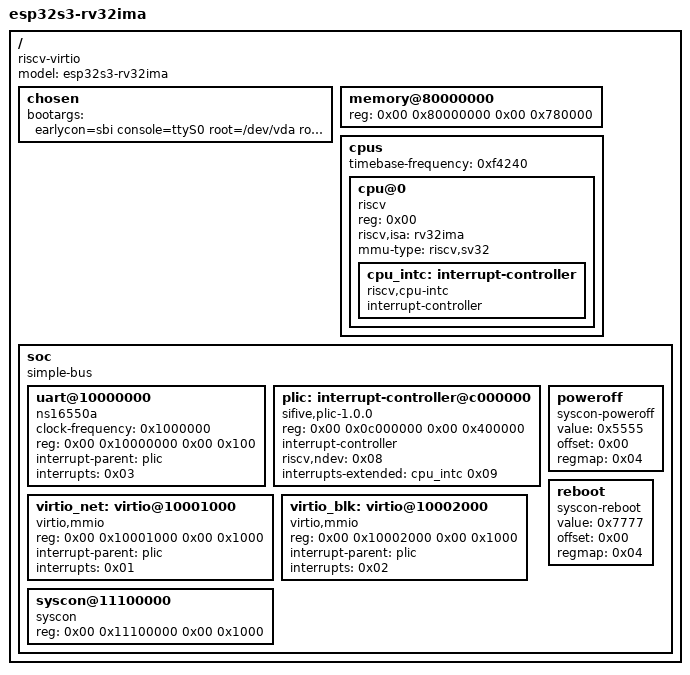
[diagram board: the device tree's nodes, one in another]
/dts-v1/;

/ {
	#address-cells = <0x02>;
	#size-cells = <0x02>;
	compatible = "riscv-virtio";
	model = "esp32s3-rv32ima";

	chosen {
		bootargs = "earlycon=sbi console=ttyS0 root=/dev/vda rootfstype=ext4 rootwait rw";
	};

	memory@80000000 {
		device_type = "memory";
		/* 7.5MB guest RAM. The external DTB is kept above this range. */
		reg = <0x00 0x80000000 0x00 0x780000>;
	};

	cpus {
		#address-cells = <0x01>;
		#size-cells = <0x00>;
		timebase-frequency = <0xf4240>;

		cpu@0 {
			phandle = <0x01>;
			device_type = "cpu";
			reg = <0x00>;
			status = "okay";
			compatible = "riscv";
			riscv,isa = "rv32ima";
			mmu-type = "riscv,sv32";

			cpu_intc: interrupt-controller {
				#interrupt-cells = <0x01>;
				interrupt-controller;
				compatible = "riscv,cpu-intc";
				phandle = <0x02>;
			};
		};

	};

	soc {
		#address-cells = <0x02>;
		#size-cells = <0x02>;
		compatible = "simple-bus";
		ranges;

		uart@10000000 {
			clock-frequency = <0x1000000>;
			reg = <0x00 0x10000000 0x00 0x100>;
			compatible = "ns16550a";
			interrupt-parent = <&plic>;
			interrupts = <0x03>;
		};

		plic: interrupt-controller@c000000 {
			phandle = <0x05>;
			reg = <0x00 0x0c000000 0x00 0x400000>;
			interrupt-controller;
			#interrupt-cells = <0x01>;
			#address-cells = <0x00>;
			compatible = "sifive,plic-1.0.0";
			riscv,ndev = <0x08>;
			interrupts-extended = <&cpu_intc 0x09>; /* hart0 S-external */
		};

		virtio_net: virtio@10001000 {
			compatible = "virtio,mmio";
			reg = <0x00 0x10001000 0x00 0x1000>;
			interrupt-parent = <&plic>;
			interrupts = <0x01>;                 /* VIRTIO_NET_IRQ */
		};

		virtio_blk: virtio@10002000 {
			compatible = "virtio,mmio";
			reg = <0x00 0x10002000 0x00 0x1000>;
			interrupt-parent = <&plic>;
			interrupts = <0x02>;                 /* VIRTIO_BLK_IRQ */
		};

		poweroff {
			value = <0x5555>;
			offset = <0x00>;
			regmap = <0x04>;
			compatible = "syscon-poweroff";
		};

		reboot {
			value = <0x7777>;
			offset = <0x00>;
			regmap = <0x04>;
			compatible = "syscon-reboot";
		};

		syscon@11100000 {
			phandle = <0x04>;
			reg = <0x00 0x11100000 0x00 0x1000>;
			compatible = "syscon";
		};

	};
};
